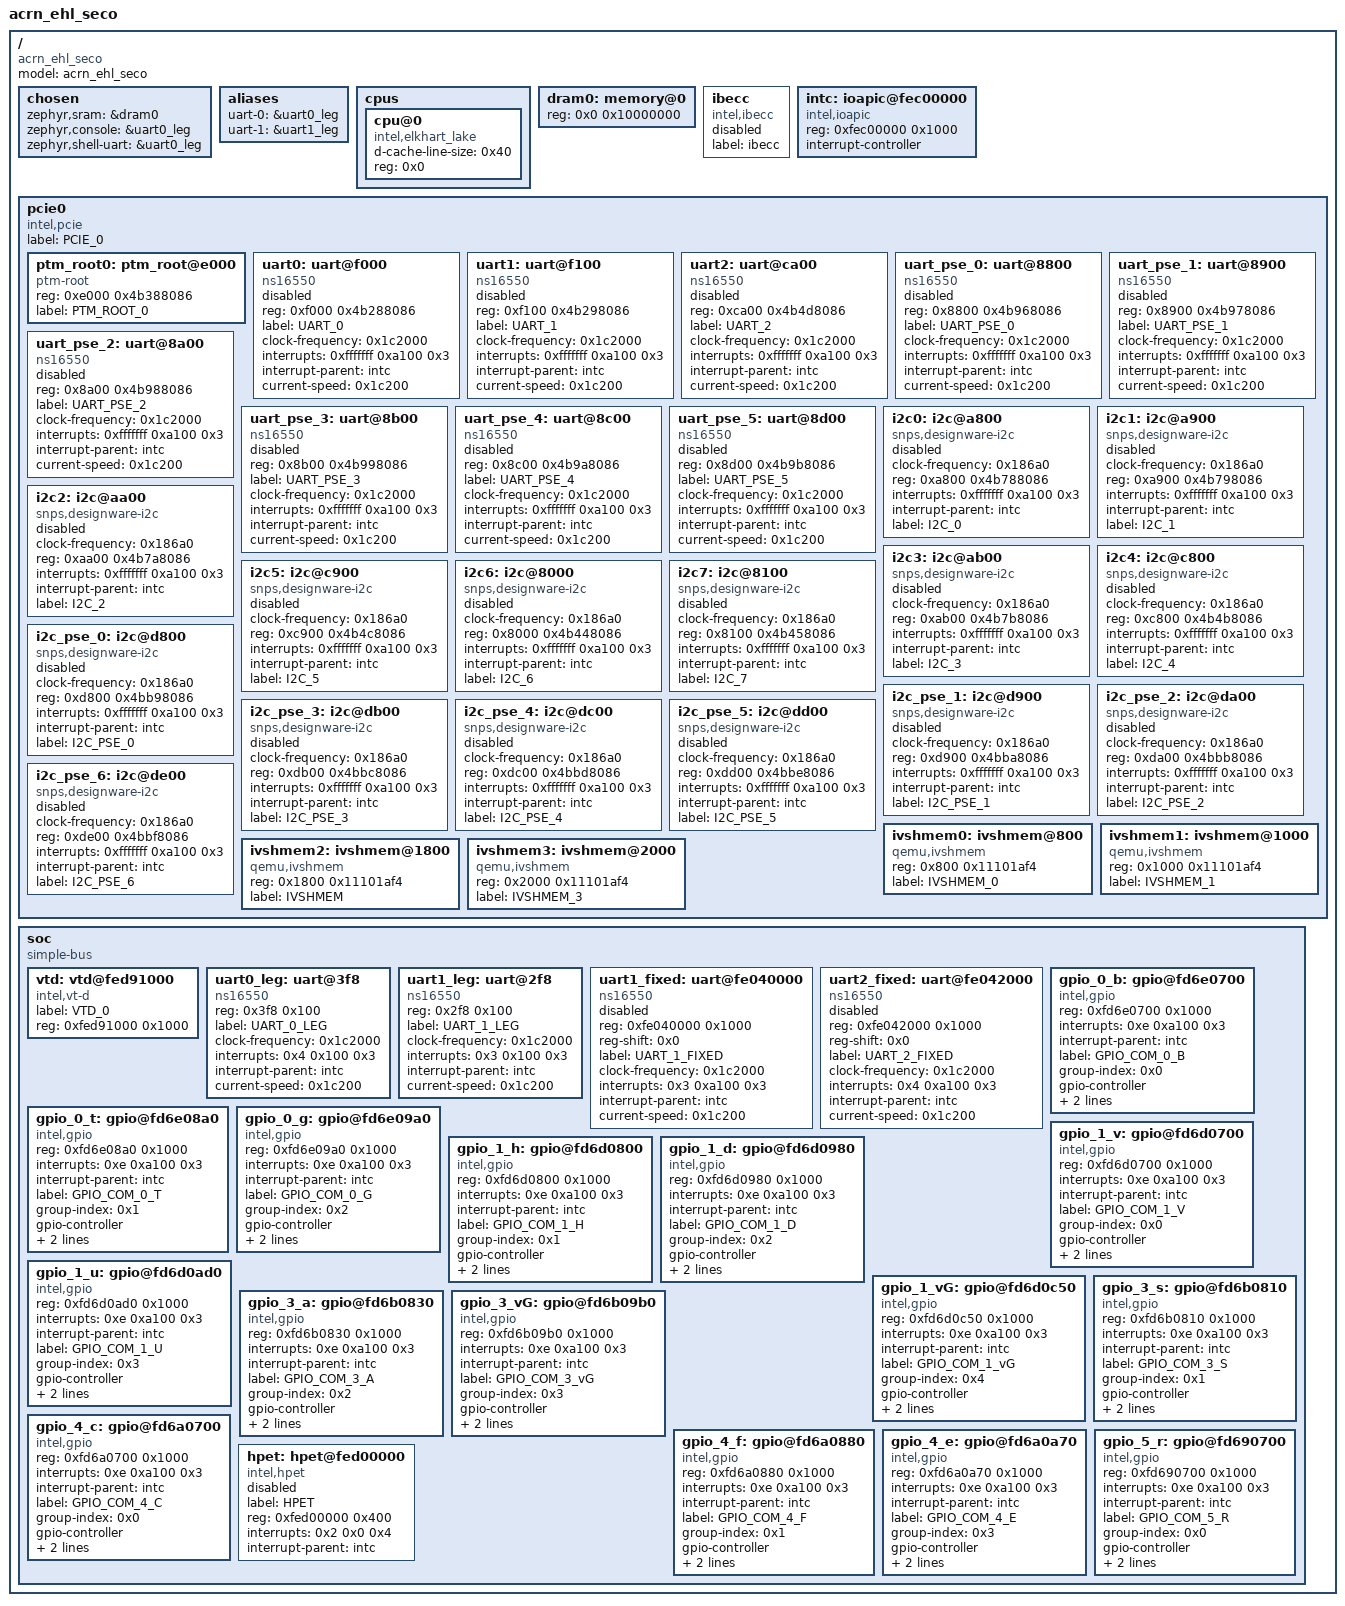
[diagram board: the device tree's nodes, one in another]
/dts-v1/;

/ {
	#address-cells = < 0x1 >;
	#size-cells = < 0x1 >;
	model = "acrn_ehl_seco";
	compatible = "acrn_ehl_seco";
	chosen {
		zephyr,sram = &dram0;
		zephyr,console = &uart0_leg;
		zephyr,shell-uart = &uart0_leg;
	};
	aliases {
		uart-0 = &uart0_leg;
		uart-1 = &uart1_leg;
	};
	cpus {
		#address-cells = < 0x1 >;
		#size-cells = < 0x0 >;
		cpu@0 {
			device_type = "cpu";
			compatible = "intel,elkhart_lake";
			d-cache-line-size = < 0x40 >;
			reg = < 0x0 >;
		};
	};
	dram0: memory@0 {
		device_type = "memory";
		reg = < 0x0 0x10000000 >;
	};
	ibecc: ibecc {
		compatible = "intel,ibecc";
		label = "ibecc";
		status = "disabled";
	};
	intc: ioapic@fec00000 {
		compatible = "intel,ioapic";
		reg = < 0xfec00000 0x1000 >;
		interrupt-controller;
		#interrupt-cells = < 0x3 >;
		phandle = < 0x1 >;
	};
	pcie0 {
		label = "PCIE_0";
		#address-cells = < 0x1 >;
		#size-cells = < 0x1 >;
		compatible = "intel,pcie";
		ranges;
		ptm_root0: ptm_root@e000 {
			compatible = "ptm-root";
			reg = < 0xe000 0x4b388086 >;
			label = "PTM_ROOT_0";
			status = "okay";
		};
		uart0: uart@f000 {
			compatible = "ns16550";
			reg = < 0xf000 0x4b288086 >;
			label = "UART_0";
			clock-frequency = < 0x1c2000 >;
			interrupts = < 0xfffffff 0xa100 0x3 >;
			interrupt-parent = < &intc >;
			status = "disabled";
			current-speed = < 0x1c200 >;
		};
		uart1: uart@f100 {
			compatible = "ns16550";
			reg = < 0xf100 0x4b298086 >;
			label = "UART_1";
			clock-frequency = < 0x1c2000 >;
			interrupts = < 0xfffffff 0xa100 0x3 >;
			interrupt-parent = < &intc >;
			status = "disabled";
			current-speed = < 0x1c200 >;
		};
		uart2: uart@ca00 {
			compatible = "ns16550";
			reg = < 0xca00 0x4b4d8086 >;
			label = "UART_2";
			clock-frequency = < 0x1c2000 >;
			interrupts = < 0xfffffff 0xa100 0x3 >;
			interrupt-parent = < &intc >;
			status = "disabled";
			current-speed = < 0x1c200 >;
		};
		uart_pse_0: uart@8800 {
			compatible = "ns16550";
			reg = < 0x8800 0x4b968086 >;
			label = "UART_PSE_0";
			clock-frequency = < 0x1c2000 >;
			interrupts = < 0xfffffff 0xa100 0x3 >;
			interrupt-parent = < &intc >;
			status = "disabled";
			current-speed = < 0x1c200 >;
		};
		uart_pse_1: uart@8900 {
			compatible = "ns16550";
			reg = < 0x8900 0x4b978086 >;
			label = "UART_PSE_1";
			clock-frequency = < 0x1c2000 >;
			interrupts = < 0xfffffff 0xa100 0x3 >;
			interrupt-parent = < &intc >;
			status = "disabled";
			current-speed = < 0x1c200 >;
		};
		uart_pse_2: uart@8a00 {
			compatible = "ns16550";
			reg = < 0x8a00 0x4b988086 >;
			label = "UART_PSE_2";
			clock-frequency = < 0x1c2000 >;
			interrupts = < 0xfffffff 0xa100 0x3 >;
			interrupt-parent = < &intc >;
			status = "disabled";
			current-speed = < 0x1c200 >;
		};
		uart_pse_3: uart@8b00 {
			compatible = "ns16550";
			reg = < 0x8b00 0x4b998086 >;
			label = "UART_PSE_3";
			clock-frequency = < 0x1c2000 >;
			interrupts = < 0xfffffff 0xa100 0x3 >;
			interrupt-parent = < &intc >;
			status = "disabled";
			current-speed = < 0x1c200 >;
		};
		uart_pse_4: uart@8c00 {
			compatible = "ns16550";
			reg = < 0x8c00 0x4b9a8086 >;
			label = "UART_PSE_4";
			clock-frequency = < 0x1c2000 >;
			interrupts = < 0xfffffff 0xa100 0x3 >;
			interrupt-parent = < &intc >;
			status = "disabled";
			current-speed = < 0x1c200 >;
		};
		uart_pse_5: uart@8d00 {
			compatible = "ns16550";
			reg = < 0x8d00 0x4b9b8086 >;
			label = "UART_PSE_5";
			clock-frequency = < 0x1c2000 >;
			interrupts = < 0xfffffff 0xa100 0x3 >;
			interrupt-parent = < &intc >;
			status = "disabled";
			current-speed = < 0x1c200 >;
		};
		i2c0: i2c@a800 {
			compatible = "snps,designware-i2c";
			clock-frequency = < 0x186a0 >;
			#address-cells = < 0x1 >;
			#size-cells = < 0x0 >;
			reg = < 0xa800 0x4b788086 >;
			interrupts = < 0xfffffff 0xa100 0x3 >;
			interrupt-parent = < &intc >;
			label = "I2C_0";
			status = "disabled";
		};
		i2c1: i2c@a900 {
			compatible = "snps,designware-i2c";
			clock-frequency = < 0x186a0 >;
			#address-cells = < 0x1 >;
			#size-cells = < 0x0 >;
			reg = < 0xa900 0x4b798086 >;
			interrupts = < 0xfffffff 0xa100 0x3 >;
			interrupt-parent = < &intc >;
			label = "I2C_1";
			status = "disabled";
		};
		i2c2: i2c@aa00 {
			compatible = "snps,designware-i2c";
			clock-frequency = < 0x186a0 >;
			#address-cells = < 0x1 >;
			#size-cells = < 0x0 >;
			reg = < 0xaa00 0x4b7a8086 >;
			interrupts = < 0xfffffff 0xa100 0x3 >;
			interrupt-parent = < &intc >;
			label = "I2C_2";
			status = "disabled";
		};
		i2c3: i2c@ab00 {
			compatible = "snps,designware-i2c";
			clock-frequency = < 0x186a0 >;
			#address-cells = < 0x1 >;
			#size-cells = < 0x0 >;
			reg = < 0xab00 0x4b7b8086 >;
			interrupts = < 0xfffffff 0xa100 0x3 >;
			interrupt-parent = < &intc >;
			label = "I2C_3";
			status = "disabled";
		};
		i2c4: i2c@c800 {
			compatible = "snps,designware-i2c";
			clock-frequency = < 0x186a0 >;
			#address-cells = < 0x1 >;
			#size-cells = < 0x0 >;
			reg = < 0xc800 0x4b4b8086 >;
			interrupts = < 0xfffffff 0xa100 0x3 >;
			interrupt-parent = < &intc >;
			label = "I2C_4";
			status = "disabled";
		};
		i2c5: i2c@c900 {
			compatible = "snps,designware-i2c";
			clock-frequency = < 0x186a0 >;
			#address-cells = < 0x1 >;
			#size-cells = < 0x0 >;
			reg = < 0xc900 0x4b4c8086 >;
			interrupts = < 0xfffffff 0xa100 0x3 >;
			interrupt-parent = < &intc >;
			label = "I2C_5";
			status = "disabled";
		};
		i2c6: i2c@8000 {
			compatible = "snps,designware-i2c";
			clock-frequency = < 0x186a0 >;
			#address-cells = < 0x1 >;
			#size-cells = < 0x0 >;
			reg = < 0x8000 0x4b448086 >;
			interrupts = < 0xfffffff 0xa100 0x3 >;
			interrupt-parent = < &intc >;
			label = "I2C_6";
			status = "disabled";
		};
		i2c7: i2c@8100 {
			compatible = "snps,designware-i2c";
			clock-frequency = < 0x186a0 >;
			#address-cells = < 0x1 >;
			#size-cells = < 0x0 >;
			reg = < 0x8100 0x4b458086 >;
			interrupts = < 0xfffffff 0xa100 0x3 >;
			interrupt-parent = < &intc >;
			label = "I2C_7";
			status = "disabled";
		};
		i2c_pse_0: i2c@d800 {
			compatible = "snps,designware-i2c";
			clock-frequency = < 0x186a0 >;
			#address-cells = < 0x1 >;
			#size-cells = < 0x0 >;
			reg = < 0xd800 0x4bb98086 >;
			interrupts = < 0xfffffff 0xa100 0x3 >;
			interrupt-parent = < &intc >;
			label = "I2C_PSE_0";
			status = "disabled";
		};
		i2c_pse_1: i2c@d900 {
			compatible = "snps,designware-i2c";
			clock-frequency = < 0x186a0 >;
			#address-cells = < 0x1 >;
			#size-cells = < 0x0 >;
			reg = < 0xd900 0x4bba8086 >;
			interrupts = < 0xfffffff 0xa100 0x3 >;
			interrupt-parent = < &intc >;
			label = "I2C_PSE_1";
			status = "disabled";
		};
		i2c_pse_2: i2c@da00 {
			compatible = "snps,designware-i2c";
			clock-frequency = < 0x186a0 >;
			#address-cells = < 0x1 >;
			#size-cells = < 0x0 >;
			reg = < 0xda00 0x4bbb8086 >;
			interrupts = < 0xfffffff 0xa100 0x3 >;
			interrupt-parent = < &intc >;
			label = "I2C_PSE_2";
			status = "disabled";
		};
		i2c_pse_3: i2c@db00 {
			compatible = "snps,designware-i2c";
			clock-frequency = < 0x186a0 >;
			#address-cells = < 0x1 >;
			#size-cells = < 0x0 >;
			reg = < 0xdb00 0x4bbc8086 >;
			interrupts = < 0xfffffff 0xa100 0x3 >;
			interrupt-parent = < &intc >;
			label = "I2C_PSE_3";
			status = "disabled";
		};
		i2c_pse_4: i2c@dc00 {
			compatible = "snps,designware-i2c";
			clock-frequency = < 0x186a0 >;
			#address-cells = < 0x1 >;
			#size-cells = < 0x0 >;
			reg = < 0xdc00 0x4bbd8086 >;
			interrupts = < 0xfffffff 0xa100 0x3 >;
			interrupt-parent = < &intc >;
			label = "I2C_PSE_4";
			status = "disabled";
		};
		i2c_pse_5: i2c@dd00 {
			compatible = "snps,designware-i2c";
			clock-frequency = < 0x186a0 >;
			#address-cells = < 0x1 >;
			#size-cells = < 0x0 >;
			reg = < 0xdd00 0x4bbe8086 >;
			interrupts = < 0xfffffff 0xa100 0x3 >;
			interrupt-parent = < &intc >;
			label = "I2C_PSE_5";
			status = "disabled";
		};
		i2c_pse_6: i2c@de00 {
			compatible = "snps,designware-i2c";
			clock-frequency = < 0x186a0 >;
			#address-cells = < 0x1 >;
			#size-cells = < 0x0 >;
			reg = < 0xde00 0x4bbf8086 >;
			interrupts = < 0xfffffff 0xa100 0x3 >;
			interrupt-parent = < &intc >;
			label = "I2C_PSE_6";
			status = "disabled";
		};
		ivshmem0: ivshmem@800 {
			compatible = "qemu,ivshmem";
			reg = < 0x800 0x11101af4 >;
			label = "IVSHMEM_0";
			status = "okay";
		};
		ivshmem1: ivshmem@1000 {
			compatible = "qemu,ivshmem";
			reg = < 0x1000 0x11101af4 >;
			label = "IVSHMEM_1";
			status = "okay";
		};
		ivshmem2: ivshmem@1800 {
			compatible = "qemu,ivshmem";
			reg = < 0x1800 0x11101af4 >;
			label = "IVSHMEM";
			status = "okay";
		};
		ivshmem3: ivshmem@2000 {
			compatible = "qemu,ivshmem";
			reg = < 0x2000 0x11101af4 >;
			label = "IVSHMEM_3";
			status = "okay";
		};
	};
	soc {
		#address-cells = < 0x1 >;
		#size-cells = < 0x1 >;
		compatible = "simple-bus";
		ranges;
		vtd: vtd@fed91000 {
			compatible = "intel,vt-d";
			label = "VTD_0";
			reg = < 0xfed91000 0x1000 >;
			status = "okay";
		};
		uart0_leg: uart@3f8 {
			compatible = "ns16550";
			reg = < 0x3f8 0x100 >;
			label = "UART_0_LEG";
			clock-frequency = < 0x1c2000 >;
			interrupts = < 0x4 0x100 0x3 >;
			interrupt-parent = < &intc >;
			status = "okay";
			current-speed = < 0x1c200 >;
		};
		uart1_leg: uart@2f8 {
			compatible = "ns16550";
			reg = < 0x2f8 0x100 >;
			label = "UART_1_LEG";
			clock-frequency = < 0x1c2000 >;
			interrupts = < 0x3 0x100 0x3 >;
			interrupt-parent = < &intc >;
			status = "okay";
			current-speed = < 0x1c200 >;
		};
		uart1_fixed: uart@fe040000 {
			compatible = "ns16550";
			reg = < 0xfe040000 0x1000 >;
			reg-shift = < 0x0 >;
			label = "UART_1_FIXED";
			clock-frequency = < 0x1c2000 >;
			interrupts = < 0x3 0xa100 0x3 >;
			interrupt-parent = < &intc >;
			status = "disabled";
			current-speed = < 0x1c200 >;
		};
		uart2_fixed: uart@fe042000 {
			compatible = "ns16550";
			reg = < 0xfe042000 0x1000 >;
			reg-shift = < 0x0 >;
			label = "UART_2_FIXED";
			clock-frequency = < 0x1c2000 >;
			interrupts = < 0x4 0xa100 0x3 >;
			interrupt-parent = < &intc >;
			status = "disabled";
			current-speed = < 0x1c200 >;
		};
		gpio_0_b: gpio@fd6e0700 {
			compatible = "intel,gpio";
			reg = < 0xfd6e0700 0x1000 >;
			interrupts = < 0xe 0xa100 0x3 >;
			interrupt-parent = < &intc >;
			label = "GPIO_COM_0_B";
			group-index = < 0x0 >;
			gpio-controller;
			#gpio-cells = < 0x2 >;
			ngpios = < 0x18 >;
			pin-offset = < 0x0 >;
			status = "okay";
		};
		gpio_0_t: gpio@fd6e08a0 {
			compatible = "intel,gpio";
			reg = < 0xfd6e08a0 0x1000 >;
			interrupts = < 0xe 0xa100 0x3 >;
			interrupt-parent = < &intc >;
			label = "GPIO_COM_0_T";
			group-index = < 0x1 >;
			gpio-controller;
			#gpio-cells = < 0x2 >;
			ngpios = < 0x10 >;
			pin-offset = < 0x1a >;
			status = "okay";
		};
		gpio_0_g: gpio@fd6e09a0 {
			compatible = "intel,gpio";
			reg = < 0xfd6e09a0 0x1000 >;
			interrupts = < 0xe 0xa100 0x3 >;
			interrupt-parent = < &intc >;
			label = "GPIO_COM_0_G";
			group-index = < 0x2 >;
			gpio-controller;
			#gpio-cells = < 0x2 >;
			ngpios = < 0x18 >;
			pin-offset = < 0x2a >;
			status = "okay";
		};
		gpio_1_v: gpio@fd6d0700 {
			compatible = "intel,gpio";
			reg = < 0xfd6d0700 0x1000 >;
			interrupts = < 0xe 0xa100 0x3 >;
			interrupt-parent = < &intc >;
			label = "GPIO_COM_1_V";
			group-index = < 0x0 >;
			gpio-controller;
			#gpio-cells = < 0x2 >;
			ngpios = < 0x10 >;
			pin-offset = < 0x0 >;
			status = "okay";
		};
		gpio_1_h: gpio@fd6d0800 {
			compatible = "intel,gpio";
			reg = < 0xfd6d0800 0x1000 >;
			interrupts = < 0xe 0xa100 0x3 >;
			interrupt-parent = < &intc >;
			label = "GPIO_COM_1_H";
			group-index = < 0x1 >;
			gpio-controller;
			#gpio-cells = < 0x2 >;
			ngpios = < 0x18 >;
			pin-offset = < 0x10 >;
			status = "okay";
		};
		gpio_1_d: gpio@fd6d0980 {
			compatible = "intel,gpio";
			reg = < 0xfd6d0980 0x1000 >;
			interrupts = < 0xe 0xa100 0x3 >;
			interrupt-parent = < &intc >;
			label = "GPIO_COM_1_D";
			group-index = < 0x2 >;
			gpio-controller;
			#gpio-cells = < 0x2 >;
			ngpios = < 0x14 >;
			pin-offset = < 0x28 >;
			status = "okay";
		};
		gpio_1_u: gpio@fd6d0ad0 {
			compatible = "intel,gpio";
			reg = < 0xfd6d0ad0 0x1000 >;
			interrupts = < 0xe 0xa100 0x3 >;
			interrupt-parent = < &intc >;
			label = "GPIO_COM_1_U";
			group-index = < 0x3 >;
			gpio-controller;
			#gpio-cells = < 0x2 >;
			ngpios = < 0x14 >;
			pin-offset = < 0x3d >;
			status = "okay";
		};
		gpio_1_vG: gpio@fd6d0c50 {
			compatible = "intel,gpio";
			reg = < 0xfd6d0c50 0x1000 >;
			interrupts = < 0xe 0xa100 0x3 >;
			interrupt-parent = < &intc >;
			label = "GPIO_COM_1_vG";
			group-index = < 0x4 >;
			gpio-controller;
			#gpio-cells = < 0x2 >;
			ngpios = < 0x1c >;
			pin-offset = < 0x55 >;
			status = "okay";
		};
		gpio_3_s: gpio@fd6b0810 {
			compatible = "intel,gpio";
			reg = < 0xfd6b0810 0x1000 >;
			interrupts = < 0xe 0xa100 0x3 >;
			interrupt-parent = < &intc >;
			label = "GPIO_COM_3_S";
			group-index = < 0x1 >;
			gpio-controller;
			#gpio-cells = < 0x2 >;
			ngpios = < 0x2 >;
			pin-offset = < 0x11 >;
			status = "okay";
		};
		gpio_3_a: gpio@fd6b0830 {
			compatible = "intel,gpio";
			reg = < 0xfd6b0830 0x1000 >;
			interrupts = < 0xe 0xa100 0x3 >;
			interrupt-parent = < &intc >;
			label = "GPIO_COM_3_A";
			group-index = < 0x2 >;
			gpio-controller;
			#gpio-cells = < 0x2 >;
			ngpios = < 0x18 >;
			pin-offset = < 0x19 >;
			status = "okay";
		};
		gpio_3_vG: gpio@fd6b09b0 {
			compatible = "intel,gpio";
			reg = < 0xfd6b09b0 0x1000 >;
			interrupts = < 0xe 0xa100 0x3 >;
			interrupt-parent = < &intc >;
			label = "GPIO_COM_3_vG";
			group-index = < 0x3 >;
			gpio-controller;
			#gpio-cells = < 0x2 >;
			ngpios = < 0x4 >;
			pin-offset = < 0x31 >;
			status = "okay";
		};
		gpio_4_c: gpio@fd6a0700 {
			compatible = "intel,gpio";
			reg = < 0xfd6a0700 0x1000 >;
			interrupts = < 0xe 0xa100 0x3 >;
			interrupt-parent = < &intc >;
			label = "GPIO_COM_4_C";
			group-index = < 0x0 >;
			gpio-controller;
			#gpio-cells = < 0x2 >;
			ngpios = < 0x18 >;
			pin-offset = < 0x0 >;
			status = "okay";
		};
		gpio_4_f: gpio@fd6a0880 {
			compatible = "intel,gpio";
			reg = < 0xfd6a0880 0x1000 >;
			interrupts = < 0xe 0xa100 0x3 >;
			interrupt-parent = < &intc >;
			label = "GPIO_COM_4_F";
			group-index = < 0x1 >;
			gpio-controller;
			#gpio-cells = < 0x2 >;
			ngpios = < 0x18 >;
			pin-offset = < 0x18 >;
			status = "okay";
		};
		gpio_4_e: gpio@fd6a0a70 {
			compatible = "intel,gpio";
			reg = < 0xfd6a0a70 0x1000 >;
			interrupts = < 0xe 0xa100 0x3 >;
			interrupt-parent = < &intc >;
			label = "GPIO_COM_4_E";
			group-index = < 0x3 >;
			gpio-controller;
			#gpio-cells = < 0x2 >;
			ngpios = < 0x18 >;
			pin-offset = < 0x39 >;
			status = "okay";
		};
		gpio_5_r: gpio@fd690700 {
			compatible = "intel,gpio";
			reg = < 0xfd690700 0x1000 >;
			interrupts = < 0xe 0xa100 0x3 >;
			interrupt-parent = < &intc >;
			label = "GPIO_COM_5_R";
			group-index = < 0x0 >;
			gpio-controller;
			#gpio-cells = < 0x2 >;
			ngpios = < 0x8 >;
			pin-offset = < 0x0 >;
			status = "okay";
		};
		hpet: hpet@fed00000 {
			label = "HPET";
			compatible = "intel,hpet";
			reg = < 0xfed00000 0x400 >;
			interrupts = < 0x2 0x0 0x4 >;
			interrupt-parent = < &intc >;
			status = "disabled";
		};
	};
};
